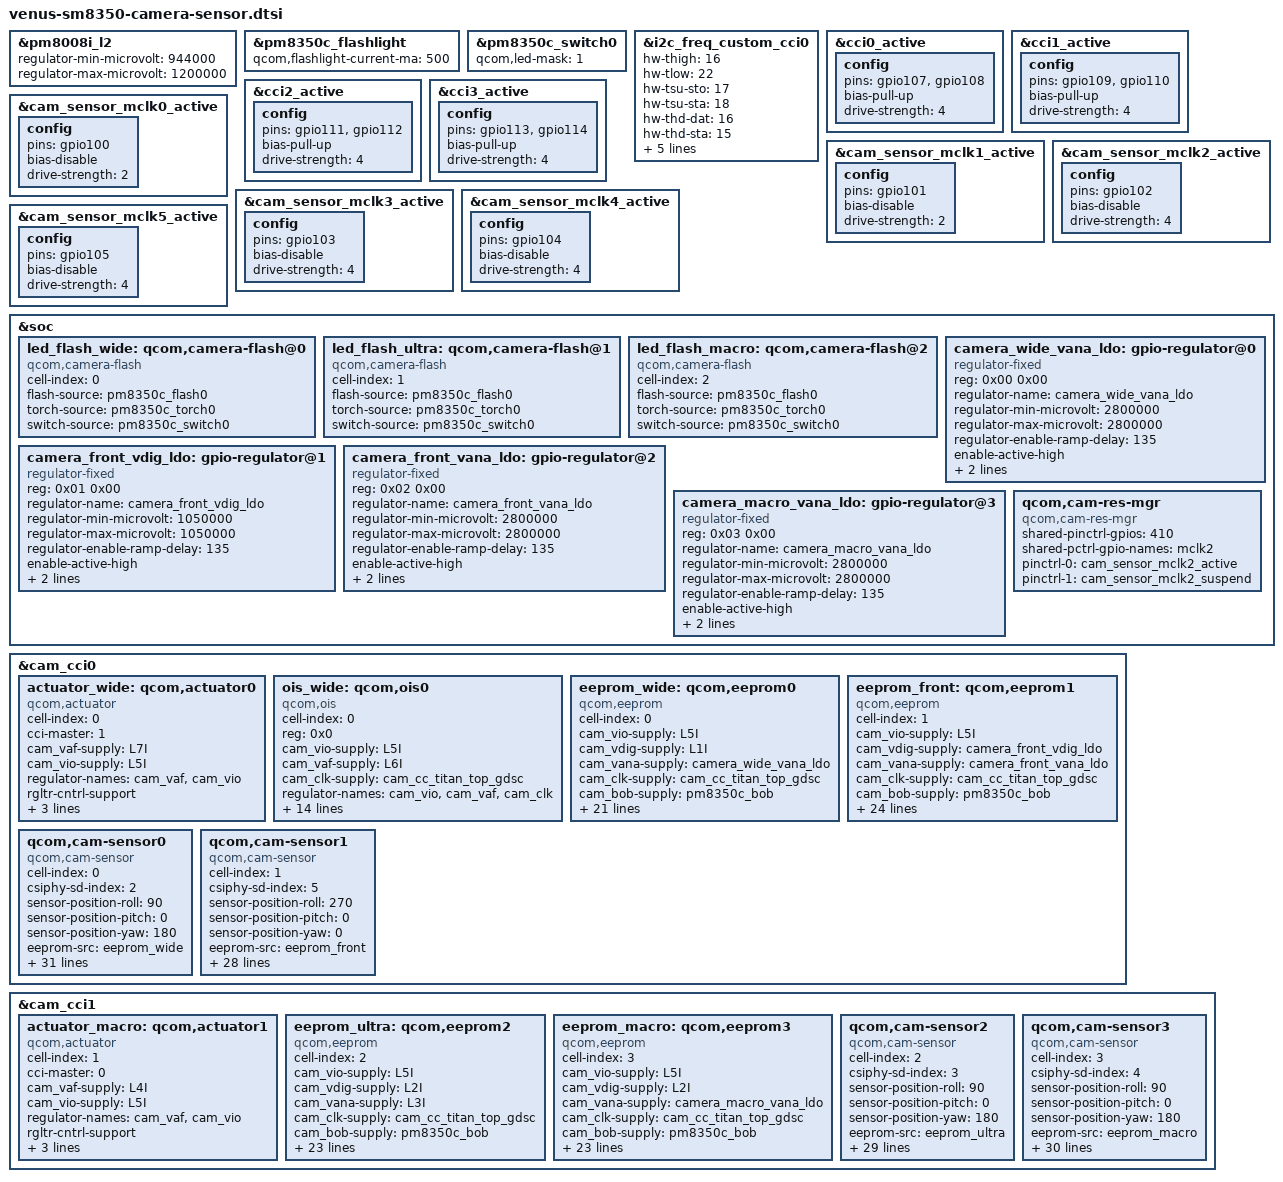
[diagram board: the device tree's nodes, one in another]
#include <dt-bindings/clock/qcom,camcc-lahaina.h>

&pm8008i_l2 {
	regulator-min-microvolt = <944000>;
	regulator-max-microvolt = <1200000>;
};

&pm8350c_flashlight{
	qcom,flashlight-current-ma = <500>;		//each torch current
};

&pm8350c_switch0 {
	qcom,led-mask = <1>; /* Channels 1*/
};

&i2c_freq_custom_cci0 {
	hw-thigh = <16>;
	hw-tlow = <22>;
	hw-tsu-sto = <17>;
	hw-tsu-sta = <18>;
	hw-thd-dat = <16>;
	hw-thd-sta = <15>;
	hw-tbuf = <24>;
	hw-scl-stretch-en = <1>;
	hw-trdhld = <3>;
	hw-tsp = <3>;
	cci-clk-src = <37500000>;
	status = "ok";
};

&cci0_active {
	config {
		pins = "gpio107","gpio108";
		bias-pull-up; /* PULL UP*/
		drive-strength = <4>; /* 4 MA */
	};
};

&cci1_active {
	config {
		pins = "gpio109","gpio110";
		bias-pull-up; /* PULL UP*/
		drive-strength = <4>; /* 4 MA */
	};
};

&cci2_active {
	config {
		pins = "gpio111","gpio112";
		bias-pull-up; /* PULL UP*/
		drive-strength = <4>; /* 4 MA */
	};
};

&cci3_active {
	config {
		pins = "gpio113","gpio114";
		bias-pull-up; /* PULL UP*/
		drive-strength = <4>; /* 4 MA */
	};
};

&cam_sensor_mclk0_active {
	/* MCLK0 */
	config {
		pins = "gpio100";
		bias-disable; /* No PULL */
		drive-strength = <2>; /* 4 MA */
	};
};

&cam_sensor_mclk1_active {
	/* MCLK1 */
	config {
		pins = "gpio101";
		bias-disable; /* No PULL */
		drive-strength = <2>; /* 4 MA */
	};
};

&cam_sensor_mclk2_active {
	/* MCLK2 */
	config {
		pins = "gpio102";
		bias-disable; /* No PULL */
		drive-strength = <4>; /* 4 MA */
	};
};

&cam_sensor_mclk3_active {
	/* MCLK3 */
	config {
		pins = "gpio103";
		bias-disable; /* No PULL */
		drive-strength = <4>; /* 4 MA */
	};
};

&cam_sensor_mclk4_active {
	/* MCLK4 */
	config {
		pins = "gpio104";
		bias-disable; /* No PULL */
		drive-strength = <4>; /* 4 MA */
	};
};

&cam_sensor_mclk5_active {
	/* MCLK5 */
	config {
		pins = "gpio105";
		bias-disable; /* No PULL */
		drive-strength = <4>; /* 4 MA */
	};
};

&soc {
	led_flash_wide: qcom,camera-flash@0 {
		cell-index = <0>;
		compatible = "qcom,camera-flash";
		flash-source = <&pm8350c_flash0>;
		torch-source = <&pm8350c_torch0>;
		switch-source = <&pm8350c_switch0>;
		status = "ok";
	};

	led_flash_ultra: qcom,camera-flash@1 {
		cell-index = <1>;
		compatible = "qcom,camera-flash";
		flash-source = <&pm8350c_flash0>;
		torch-source = <&pm8350c_torch0>;
		switch-source = <&pm8350c_switch0>;
		status = "ok";
	};

	led_flash_macro: qcom,camera-flash@2 {
		cell-index = <2>;
		compatible = "qcom,camera-flash";
		flash-source = <&pm8350c_flash0>;
		torch-source = <&pm8350c_torch0>;
		switch-source = <&pm8350c_switch0>;
		status = "ok";
	};

	camera_wide_vana_ldo: gpio-regulator@0 {
		compatible = "regulator-fixed";
		reg = <0x00 0x00>;
		regulator-name = "camera_wide_vana_ldo";
		regulator-min-microvolt = <2800000>;
		regulator-max-microvolt = <2800000>;
		regulator-enable-ramp-delay = <135>;
		enable-active-high;
		gpio = <&tlmm 12 0>;
		vin-supply = <&pm8350c_bob>;
	};

	camera_front_vdig_ldo: gpio-regulator@1 {
		compatible = "regulator-fixed";
		reg = <0x01 0x00>;
		regulator-name = "camera_front_vdig_ldo";
		regulator-min-microvolt = <1050000>;
		regulator-max-microvolt = <1050000>;
		regulator-enable-ramp-delay = <135>;
		enable-active-high;
		gpio = <&tlmm 93 0>;
		vin-supply = <&S12B>;
	};

	camera_front_vana_ldo: gpio-regulator@2 {
		compatible = "regulator-fixed";
		reg = <0x02 0x00>;
		regulator-name = "camera_front_vana_ldo";
		regulator-min-microvolt = <2800000>;
		regulator-max-microvolt = <2800000>;
		regulator-enable-ramp-delay = <135>;
		enable-active-high;
		gpio = <&tlmm 66 0>;
		vin-supply = <&pm8350c_bob>;
	};

	camera_macro_vana_ldo: gpio-regulator@3 {
		compatible = "regulator-fixed";
		reg = <0x03 0x00>;
		regulator-name = "camera_macro_vana_ldo";
		regulator-min-microvolt = <2800000>;
		regulator-max-microvolt = <2800000>;
		regulator-enable-ramp-delay = <135>;
		enable-active-high;
		gpio = <&tlmm 34 0>;
		vin-supply = <&pm8350c_bob>;
	};

	qcom,cam-res-mgr {
		compatible = "qcom,cam-res-mgr";
		shared-pinctrl-gpios = <410>;
		shared-pctrl-gpio-names = "mclk2";
		pinctrl-names = "mclk2_active", "mclk2_suspend";
		pinctrl-0 = <&cam_sensor_mclk2_active>;
		pinctrl-1 = <&cam_sensor_mclk2_suspend>;
		status = "ok";
	};
};

&cam_cci0 {
	actuator_wide: qcom,actuator0 {
		cell-index = <0>;
		compatible = "qcom,actuator";
		cci-master = <1>;
		cam_vaf-supply = <&L7I>;
		cam_vio-supply = <&L5I>;
		regulator-names = "cam_vaf", "cam_vio";
		rgltr-cntrl-support;
		rgltr-min-voltage = <2800000 1800000>;
		rgltr-max-voltage = <2800000 1800000>;
		rgltr-load-current = <300000 10000>;
		status = "ok";
	};

	ois_wide: qcom,ois0 {
		cell-index = <0>;
		reg = <0x0>;
		compatible = "qcom,ois";
		cam_vio-supply = <&L5I>;
		cam_vaf-supply = <&L6I>;
		cam_clk-supply = <&cam_cc_titan_top_gdsc>;
		regulator-names = "cam_vio", "cam_vaf", "cam_clk";
		rgltr-min-voltage = <1800000 2800000 0>;
		rgltr-max-voltage = <1800000 2800000 0>;
		rgltr-load-current = <10000 280000 0>;
		use-shared-clk;
		gpio-no-mux = <0>;
		gpios = <&tlmm 102 0>;
		gpio-req-tbl-num = <0>;
		gpio-req-tbl-flags = <1>;
		gpio-req-tbl-label = "CAMIF_MCLK2";
		clocks = <&clock_camcc CAM_CC_MCLK2_CLK>;
		clock-names = "cam_clk";
		clock-cntl-level = "nominal";
		clock-rates = <19200000>;
		rgltr-cntrl-support;
		cci-master = <1>;
		status = "ok";
	};

	eeprom_wide: qcom,eeprom0 {
		cell-index = <0>;
		compatible = "qcom,eeprom";
		cam_vio-supply = <&L5I>;
		cam_vdig-supply = <&L1I>;
		cam_vana-supply = <&camera_wide_vana_ldo>;
		cam_clk-supply = <&cam_cc_titan_top_gdsc>;
		cam_bob-supply = <&pm8350c_bob>;
		regulator-names = "cam_vio", "cam_vdig", "cam_vana",
			"cam_clk", "cam_bob";
		rgltr-cntrl-support;
		rgltr-min-voltage = <1800000 1056000 2800000 0 3200000>;
		rgltr-max-voltage = <1800000 1056000 2800000 0 3960000>;
		rgltr-load-current = <10000 140000 280000 0 2000000>;
		gpio-no-mux = <0>;
		pinctrl-names = "cam_default", "cam_suspend";
		pinctrl-0 = <&cam_sensor_active_rst1>;
		pinctrl-1 = <&cam_sensor_suspend_rst1>;
		gpios = <&tlmm 102 0>,
			<&tlmm 16 0>;
		gpio-reset = <1>;
		gpio-req-tbl-num = <0 1>;
		gpio-req-tbl-flags = <1 0>;
		gpio-req-tbl-label = "CAMIF_MCLK2",
					"CAM_RESET1";
		cci-master = <1>;
		clocks = <&clock_camcc CAM_CC_MCLK2_CLK>;
		clock-names = "cam_clk";
		clock-cntl-level = "nominal";
		clock-rates = <19200000>;
		status = "ok";
	};

	eeprom_front: qcom,eeprom1 {
		cell-index = <1>;
		compatible = "qcom,eeprom";
		cam_vio-supply = <&L5I>;
		cam_vdig-supply = <&camera_front_vdig_ldo>;
		cam_vana-supply = <&camera_front_vana_ldo>;
		cam_clk-supply = <&cam_cc_titan_top_gdsc>;
		cam_bob-supply = <&pm8350c_bob>;
		regulator-names = "cam_vio", "cam_vdig", "cam_vana",
			"cam_clk", "cam_bob";
		rgltr-cntrl-support;
		rgltr-min-voltage = <1800000 1050000 2800000 0 3200000>;
		rgltr-max-voltage = <1800000 1050000 2800000 0 3960000>;
		rgltr-load-current = <10000 140000 280000 0 2000000>;
		gpio-no-mux = <0>;
		use-shared-clk;
		pinctrl-names = "cam_default", "cam_suspend";
		pinctrl-0 = <&cam_sensor_mclk5_active
				&cam_sensor_active_rst0>;
		pinctrl-1 = <&cam_sensor_mclk5_suspend
				&cam_sensor_suspend_rst0>;
		gpios = <&tlmm 105 0>,
			<&tlmm 17 0>;
		gpio-reset = <1>;
		gpio-req-tbl-num = <0 1>;
		gpio-req-tbl-flags = <1 0>;
		gpio-req-tbl-label = "CAMIF_MCLK5",
					"CAM_RESET0";
		cci-master = <0>;
		clocks = <&clock_camcc CAM_CC_MCLK5_CLK>;
		clock-names = "cam_clk";
		clock-cntl-level = "nominal";
		clock-rates = <19200000>;
		status = "ok";
	};

	// wide camera
	qcom,cam-sensor0 {
		cell-index = <0>;
		compatible = "qcom,cam-sensor";
		csiphy-sd-index = <2>;
		sensor-position-roll = <90>;
		sensor-position-pitch = <0>;
		sensor-position-yaw = <180>;
		eeprom-src = <&eeprom_wide>;
		actuator-src = <&actuator_wide>;
		led-flash-src = <&led_flash_wide>;
		ois-src = <&ois_wide>;
		cam_vio-supply = <&L5I>;
		cam_vdig-supply = <&L1I>;
		cam_vana-supply = <&camera_wide_vana_ldo>;
		cam_vaf-supply = <&L6I>;
		cam_clk-supply = <&cam_cc_titan_top_gdsc>;
		cam_bob-supply = <&pm8350c_bob>;
		regulator-names = "cam_vio", "cam_vdig", "cam_vana", "cam_vaf",
			"cam_clk", "cam_bob";
		rgltr-cntrl-support;
		rgltr-min-voltage = <1800000 1056000 2800000 2800000 0 3200000>;
		rgltr-max-voltage = <1800000 1056000 2800000 2800000 0 3960000>;
		rgltr-load-current = <10000 140000 280000 280000 0 2000000>;
		gpio-no-mux = <0>;
		use-shared-clk;
		pinctrl-names = "cam_default", "cam_suspend";
		pinctrl-0 = <&cam_sensor_active_rst1>;
		pinctrl-1 = <&cam_sensor_suspend_rst1>;
		gpios = <&tlmm 102 0>,
			<&tlmm 16 0>;
		gpio-reset = <1>;
		gpio-req-tbl-num = <0 1>;
		gpio-req-tbl-flags = <1 0>;
		gpio-req-tbl-label = "CAMIF_MCLK2",
					"CAM_RESET1";
		cci-master = <1>;
		clocks = <&clock_camcc CAM_CC_MCLK2_CLK>;
		clock-names = "cam_clk";
		clock-cntl-level = "nominal";
		clock-rates = <19200000>;
		status = "ok";
	};

	// front camera
	qcom,cam-sensor1 {
		cell-index = <1>;
		compatible = "qcom,cam-sensor";
		csiphy-sd-index = <5>;
		sensor-position-roll = <270>;
		sensor-position-pitch = <0>;
		sensor-position-yaw = <0>;
		eeprom-src = <&eeprom_front>;
		cam_vio-supply = <&L5I>;
		cam_vdig-supply = <&camera_front_vdig_ldo>;
		cam_vana-supply = <&camera_front_vana_ldo>;
		cam_clk-supply = <&cam_cc_titan_top_gdsc>;
		cam_bob-supply = <&pm8350c_bob>;
		regulator-names = "cam_vio", "cam_vdig", "cam_vana",
			"cam_clk", "cam_bob";
		rgltr-cntrl-support;
		rgltr-min-voltage = <1800000 1050000 2800000 0 3200000>;
		rgltr-max-voltage = <1800000 1050000 2800000 0 3960000>;
		rgltr-load-current = <10000 140000 280000 0 2000000>;
		gpio-no-mux = <0>;
		pinctrl-names = "cam_default", "cam_suspend";
		pinctrl-0 = <&cam_sensor_mclk5_active
				&cam_sensor_active_rst0>;
		pinctrl-1 = <&cam_sensor_mclk5_suspend
				&cam_sensor_suspend_rst0>;
		gpios = <&tlmm 105 0>,
			<&tlmm 17 0>;
		gpio-reset = <1>;
		gpio-req-tbl-num = <0 1>;
		gpio-req-tbl-flags = <1 0>;
		gpio-req-tbl-label = "CAMIF_MCLK5",
					"CAM_RESET0";
		cci-master = <0>;
		clocks = <&clock_camcc CAM_CC_MCLK5_CLK>;
		clock-names = "cam_clk";
		clock-cntl-level = "nominal";
		clock-rates = <19200000>;
		status = "ok";
	};

};

&cam_cci1 {
	actuator_macro: qcom,actuator1 {
		cell-index = <1>;
		compatible = "qcom,actuator";
		cci-master = <0>;
		cam_vaf-supply = <&L4I>;
		cam_vio-supply = <&L5I>;
		regulator-names = "cam_vaf", "cam_vio";
		rgltr-cntrl-support;
		rgltr-min-voltage = <2800000 1800000>;
		rgltr-max-voltage = <2800000 1800000>;
		rgltr-load-current = <300000 10000>;
		status = "ok";
	};

	eeprom_ultra: qcom,eeprom2 {
		cell-index = <2>;
		compatible = "qcom,eeprom";
		cam_vio-supply = <&L5I>;
		cam_vdig-supply = <&L2I>;
		cam_vana-supply = <&L3I>;
		cam_clk-supply = <&cam_cc_titan_top_gdsc>;
		cam_bob-supply = <&pm8350c_bob>;
		regulator-names = "cam_vio", "cam_vdig", "cam_vana",
			"cam_clk", "cam_bob";
		rgltr-cntrl-support;
		rgltr-min-voltage = <1800000 1200000 2800000 0 3200000>;
		rgltr-max-voltage = <1800000 1200000 2800000 0 3960000>;
		rgltr-load-current = <10000 140000 280000 0 2000000>;
		gpio-no-mux = <0>;
		pinctrl-names = "cam_default", "cam_suspend";
		pinctrl-0 = <&cam_sensor_mclk3_active
				&cam_sensor_active_rst3>;
		pinctrl-1 = <&cam_sensor_mclk3_suspend
				&cam_sensor_suspend_rst3>;
		gpios = <&tlmm 103 0>,
			<&tlmm 117 0>;
		gpio-reset = <1>;
		gpio-req-tbl-num = <0 1>;
		gpio-req-tbl-flags = <1 0>;
		gpio-req-tbl-label = "CAMIF_MCLK3",
					"CAM_RESET3";
		cci-master = <1>;
		clocks = <&clock_camcc CAM_CC_MCLK3_CLK>;
		clock-names = "cam_clk";
		clock-cntl-level = "nominal";
		clock-rates = <19200000>;
		status = "ok";
	};

	eeprom_macro: qcom,eeprom3 {
		cell-index = <3>;
		compatible = "qcom,eeprom";
		cam_vio-supply = <&L5I>;
		cam_vdig-supply = <&L2I>;
		cam_vana-supply = <&camera_macro_vana_ldo>;
		cam_clk-supply = <&cam_cc_titan_top_gdsc>;
		cam_bob-supply = <&pm8350c_bob>;
		regulator-names = "cam_vio", "cam_vdig", "cam_vana",
			"cam_clk", "cam_bob";
		rgltr-cntrl-support;
		rgltr-min-voltage = <1800000 1200000 2800000 0 3200000>;
		rgltr-max-voltage = <1800000 1200000 2800000 0 3960000>;
		rgltr-load-current = <10000 140000 280000 0 2000000>;
		gpio-no-mux = <0>;
		pinctrl-names = "cam_default", "cam_suspend";
		pinctrl-0 = <&cam_sensor_mclk4_active
				&cam_sensor_active_rst2>;
		pinctrl-1 = <&cam_sensor_mclk4_suspend
				&cam_sensor_suspend_rst2>;
		gpios = <&tlmm 104 0>,
			<&tlmm 106 0>;
		gpio-reset = <1>;
		gpio-req-tbl-num = <0 1>;
		gpio-req-tbl-flags = <1 0>;
		gpio-req-tbl-label = "CAMIF_MCLK4",
					"CAM_RESET2";
		cci-master = <0>;
		clocks = <&clock_camcc CAM_CC_MCLK4_CLK>;
		clock-names = "cam_clk";
		clock-cntl-level = "nominal";
		clock-rates = <19200000>;
		status = "ok";
	};

	// ultra camera
	qcom,cam-sensor2 {
		cell-index = <2>;
		compatible = "qcom,cam-sensor";
		csiphy-sd-index = <3>;
		sensor-position-roll = <90>;
		sensor-position-pitch = <0>;
		sensor-position-yaw = <180>;
		eeprom-src = <&eeprom_ultra>;
		led-flash-src = <&led_flash_ultra>;
		cam_vio-supply = <&L5I>;
		cam_vdig-supply = <&L2I>;
		cam_vana-supply = <&L3I>;
		cam_clk-supply = <&cam_cc_titan_top_gdsc>;
		cam_bob-supply = <&pm8350c_bob>;
		regulator-names = "cam_vio", "cam_vdig", "cam_vana",
			"cam_clk", "cam_bob";
		rgltr-cntrl-support;
		rgltr-min-voltage = <1800000 1200000 2800000 0 3200000>;
		rgltr-max-voltage = <1800000 1200000 2800000 0 3960000>;
		rgltr-load-current = <10000 140000 280000 0 2000000>;
		gpio-no-mux = <0>;
		pinctrl-names = "cam_default", "cam_suspend";
		pinctrl-0 = <&cam_sensor_mclk3_active
				&cam_sensor_active_rst3>;
		pinctrl-1 = <&cam_sensor_mclk3_suspend
				&cam_sensor_suspend_rst3>;
		gpios = <&tlmm 103 0>,
			<&tlmm 117 0>;
		gpio-reset = <1>;
		gpio-req-tbl-num = <0 1>;
		gpio-req-tbl-flags = <1 0>;
		gpio-req-tbl-label = "CAMIF_MCLK3",
					"CAM_RESET3";
		cci-master = <1>;
		clocks = <&clock_camcc CAM_CC_MCLK3_CLK>;
		clock-names = "cam_clk";
		clock-cntl-level = "nominal";
		clock-rates = <19200000>;
		status = "ok";
	};

	// macro camera
	qcom,cam-sensor3 {
		cell-index = <3>;
		compatible = "qcom,cam-sensor";
		csiphy-sd-index = <4>;
		sensor-position-roll = <90>;
		sensor-position-pitch = <0>;
		sensor-position-yaw = <180>;
		eeprom-src = <&eeprom_macro>;
		led-flash-src = <&led_flash_macro>;
		actuator-src = <&actuator_macro>;
		cam_vio-supply = <&L5I>;
		cam_vdig-supply = <&L2I>;
		cam_vana-supply = <&camera_macro_vana_ldo>;
		cam_clk-supply = <&cam_cc_titan_top_gdsc>;
		cam_bob-supply = <&pm8350c_bob>;
		regulator-names = "cam_vio", "cam_vdig", "cam_vana",
			"cam_clk", "cam_bob";
		rgltr-cntrl-support;
		rgltr-min-voltage = <1800000 1200000 2800000 0 3200000>;
		rgltr-max-voltage = <1800000 1200000 2800000 0 3960000>;
		rgltr-load-current = <10000 140000 280000 0 2000000>;
		gpio-no-mux = <0>;
		pinctrl-names = "cam_default", "cam_suspend";
		pinctrl-0 = <&cam_sensor_mclk4_active
				&cam_sensor_active_rst2>;
		pinctrl-1 = <&cam_sensor_mclk4_suspend
				&cam_sensor_suspend_rst2>;
		gpios = <&tlmm 104 0>,
			<&tlmm 106 0>;
		gpio-reset = <1>;
		gpio-req-tbl-num = <0 1>;
		gpio-req-tbl-flags = <1 0>;
		gpio-req-tbl-label = "CAMIF_MCLK4",
					"CAM_RESET2";
		cci-master = <0>;
		clocks = <&clock_camcc CAM_CC_MCLK4_CLK>;
		clock-names = "cam_clk";
		clock-cntl-level = "nominal";
		clock-rates = <19200000>;
		status = "ok";
	};

};
